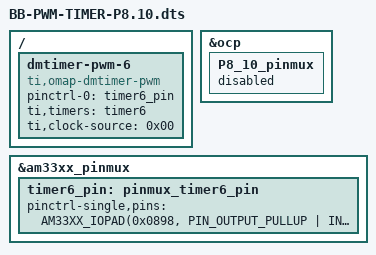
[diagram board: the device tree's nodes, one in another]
/*
 * Copyright (C) 2018 Robert Nelson <robertcnelson@gmail.com>
 *
 * This program is free software; you can redistribute it and/or modify
 * it under the terms of the GNU General Public License version 2 as
 * published by the Free Software Foundation.
 */

/dts-v1/;
/plugin/;

#include <dt-bindings/gpio/gpio.h>
#include <dt-bindings/pinctrl/am33xx.h>

/ {
	/*
	 * Free up the pins used by the cape from the pinmux helpers.
	 */
	fragment@0 {
		target = <&ocp>;
		__overlay__ {
			P8_10_pinmux { status = "disabled"; };	/* gpio2_4.timer6 */
		};
	};

	fragment@1 {
		target = <&am33xx_pinmux>;
		__overlay__ {
			timer6_pin: pinmux_timer6_pin {
				pinctrl-single,pins = <
					AM33XX_IOPAD(0x0898, PIN_OUTPUT_PULLUP | INPUT_EN | MUX_MODE2)	/* gpmc_wen.timer6 */
				>;
			};
		};
	};

	fragment@2 {
		target-path="/";
		__overlay__ {
			dmtimer-pwm-6 {
				pinctrl-names = "default";
				pinctrl-0 = <&timer6_pin>;

				compatible = "ti,omap-dmtimer-pwm";
				#pwm-cells = <3>;
				ti,timers = <&timer6>;
				//ti,prescaler = <0>;		/* 0 thru 7 */
				ti,clock-source = <0x00>;	/* timer_sys_ck */
				//ti,clock-source = <0x01>;	/* timer_32k_ck */
			};
		};
	};
};
